# STM32U575 register map
File version: 1.3
CPU: CM33 r0p1, little endian, MPU, FPU, 4 interrupt priority bits
Registers are 32-bit, read-write, reset 0x0 unless marked. A register's access mark holds for its fields unless they carry their own. Offsets are from the block's base; [hi:lo] are bit positions.

## FDCAN1_RAM
Base 0x4000AC00
Same registers: FDCAN1 0x4000A400, SEC_FDCAN1 0x5000A400, SEC_FDCAN1_RAM 0x5000AC00
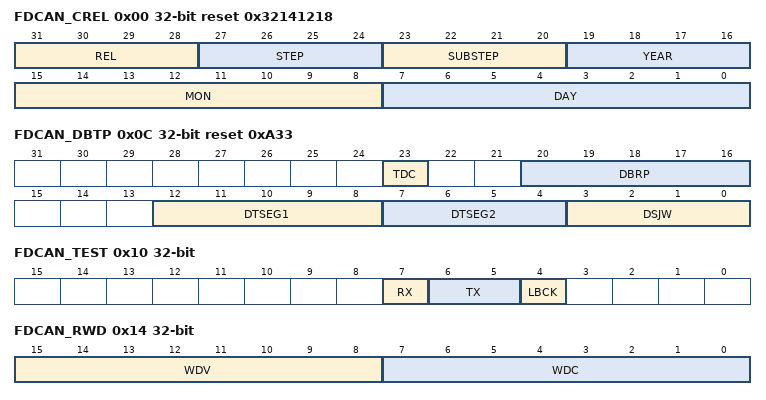
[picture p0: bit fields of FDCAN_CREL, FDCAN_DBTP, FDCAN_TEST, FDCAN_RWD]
0x00 FDCAN_CREL ro reset 0x32141218 — FDCAN Core Release Register
  [31:28] REL — Core release
  [27:24] STEP — Step of Core release
  [23:20] SUBSTEP — Sub-step of Core release
  [19:16] YEAR — Timestamp Year
  [15:8] MON — Timestamp Month
  [7:0] DAY — Timestamp Day
0x04 FDCAN_ENDN ro reset 0x87654321 — FDCAN endian register
  [31:0] ETV — Endiannes Test Value
0x0C FDCAN_DBTP reset 0xA33 — FDCAN Data Bit Timing and Prescaler Register
  [23] TDC — Transceiver Delay Compensation
  [20:16] DBRP — Data BIt Rate Prescaler
  [12:8] DTSEG1 — Data time segment after sample point
  [7:4] DTSEG2 — Data time segment after sample point
  [3:0] DSJW — Synchronization Jump Width
0x10 FDCAN_TEST access per field
  [7] RX ro — Control of Transmit Pin
  [6:5] TX rw — Loop Back mode
  [4] LBCK rw — Loop Back mode
0x14 FDCAN_RWD access per field — FDCAN RAM Watchdog Register
  [15:8] WDV ro — Watchdog value
  [7:0] WDC rw — Watchdog configuration
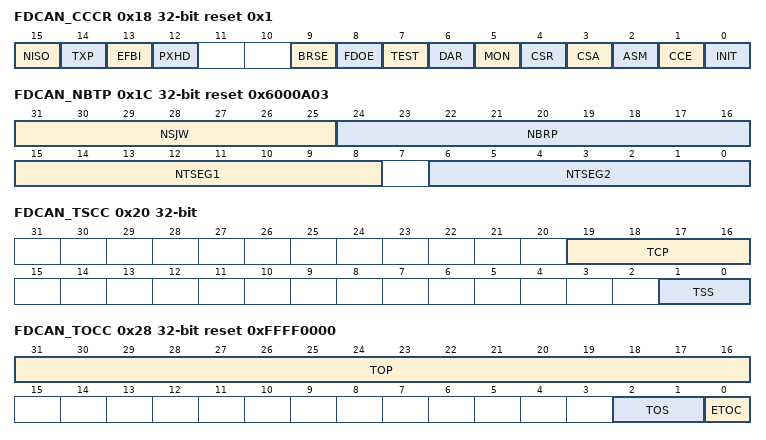
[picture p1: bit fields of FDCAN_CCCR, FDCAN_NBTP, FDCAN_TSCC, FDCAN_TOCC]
0x18 FDCAN_CCCR reset 0x1 — FDCAN CC Control Register
  [15] NISO — Non ISO Operation
  [14] TXP
  [13] EFBI — Edge Filtering during Bus Integration
  [12] PXHD — Protocol Exception Handling Disable
  [9] BRSE — FDCAN Bit Rate Switching
  [8] FDOE — FD Operation Enable
  [7] TEST — Test Mode Enable
  [6] DAR — Disable Automatic Retransmission
  [5] MON — Bus Monitoring Mode
  [4] CSR — Clock Stop Request
  [3] CSA — Clock Stop Acknowledge
  [2] ASM — ASM Restricted Operation Mode
  [1] CCE — Configuration Change Enable
  [0] INIT — Initialization
0x1C FDCAN_NBTP reset 0x6000A03 — FDCAN Nominal Bit Timing and Prescaler Register
  [31:25] NSJW — Nominal (Re)Synchronization Jump Width
  [24:16] NBRP — Bit Rate Prescaler
  [15:8] NTSEG1 — Nominal Time segment before sample point
  [6:0] NTSEG2 — Nominal Time segment after sample point
0x20 FDCAN_TSCC — FDCAN Timestamp Counter Configuration Register
  [19:16] TCP — Timestamp Counter Prescaler
  [1:0] TSS — Timestamp Select
0x24 FDCAN_TSCV — FDCAN Timestamp Counter Value Register
  [15:0] TSC — Timestamp Counter
0x28 FDCAN_TOCC reset 0xFFFF0000 — FDCAN Timeout Counter Configuration Register
  [31:16] TOP — Timeout Period
  [2:1] TOS — Timeout Select
  [0] ETOC — Enable Timeout Counter
0x2C FDCAN_TOCV reset 0xFFFF — FDCAN Timeout Counter Value Register
  [15:0] TOC — Timeout Counter
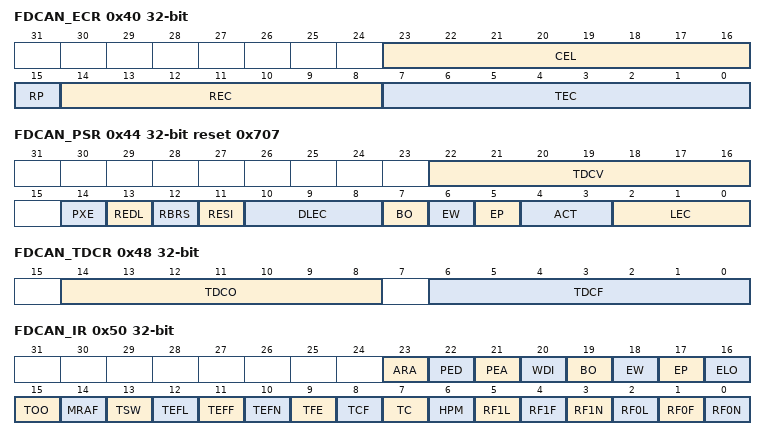
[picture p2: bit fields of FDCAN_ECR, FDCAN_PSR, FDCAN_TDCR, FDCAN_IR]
0x40 FDCAN_ECR access per field — FDCAN Error Counter Register
  [23:16] CEL rw — AN Error Logging
  [15] RP ro — Receive Error Passive
  [14:8] REC ro — Receive Error Counter
  [7:0] TEC ro — Transmit Error Counter
0x44 FDCAN_PSR access per field reset 0x707 — FDCAN Protocol Status Register
  [22:16] TDCV ro — Transmitter Delay Compensation Value
  [14] PXE rw — Protocol Exception Event
  [13] REDL rw — Received FDCAN Message
  [12] RBRS rw — BRS flag of last received FDCAN Message
  [11] RESI rw — ESI flag of last received FDCAN Message
  [10:8] DLEC rw — Data Last Error Code
  [7] BO ro — Bus_Off Status
  [6] EW ro — Warning Status
  [5] EP ro — Error Passive
  [4:3] ACT ro — Activity
  [2:0] LEC rw — Last Error Code
0x48 FDCAN_TDCR — FDCAN Transmitter Delay Compensation Register
  [14:8] TDCO — Transmitter Delay Compensation Offset
  [6:0] TDCF — Transmitter Delay Compensation Filter Window Length
0x50 FDCAN_IR — FDCAN Interrupt Register
  [23] ARA, [22] PED, [21] PEA, [20] WDI, [19] BO, [18] EW, [17] EP, [16] ELO, [15] TOO, [14] MRAF, [13] TSW, [12] TEFL, [11] TEFF, [10] TEFN, [9] TFE, [8] TCF, [7] TC, [6] HPM, [5] RF1L, [4] RF1F, [3] RF1N, [2] RF0L, [1] RF0F, [0] RF0N
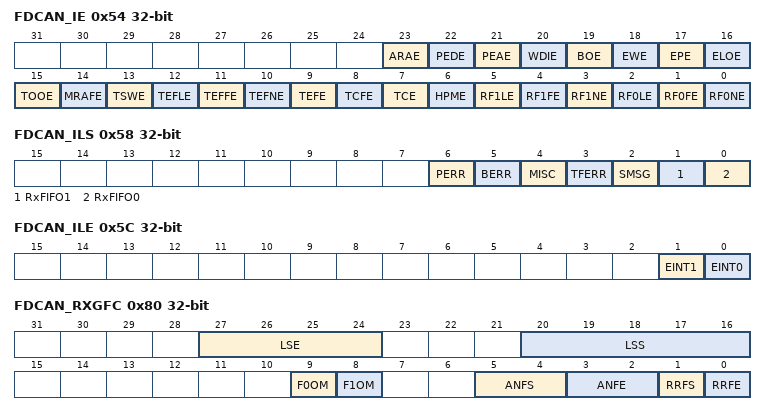
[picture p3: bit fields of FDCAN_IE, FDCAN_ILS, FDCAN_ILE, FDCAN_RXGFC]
0x54 FDCAN_IE — FDCAN Interrupt Enable Register
  [23] ARAE — Access to Reserved Address Enable
  [22] PEDE — Protocol Error in Data Phase Enable
  [21] PEAE — Protocol Error in Arbitration Phase Enable
  [20] WDIE — Watchdog Interrupt Enable
  [19] BOE — Bus_Off Status Enable
  [18] EWE — Warning Status Enable
  [17] EPE — Error Passive Enable
  [16] ELOE — Error Logging Overflow Enable
  [15] TOOE — Timeout Occurred Enable
  [14] MRAFE — Message RAM Access Failure Enable
  [13] TSWE
  [12] TEFLE — Tx Event FIFO Element Lost Enable
  [11] TEFFE — Tx Event FIFO Full Enable
  [10] TEFNE — Tx Event FIFO New Entry Enable
  [9] TEFE — Tx FIFO Empty Enable
  [8] TCFE — Transmission Cancellation Finished Enable
  [7] TCE — Transmission Completed Enable
  [6] HPME — High Priority Message Enable
  [5] RF1LE — Rx FIFO 1 Message Lost Enable
  [4] RF1FE — Rx FIFO 1 Watermark Reached Enable
  [3] RF1NE — Rx FIFO 1 New Message Enable
  [2] RF0LE — Rx FIFO 0 Message Lost Enable
  [1] RF0FE — Rx FIFO 0 Full Enable
  [0] RF0NE — Rx FIFO 0 New Message Enable
0x58 FDCAN_ILS — FDCAN Interrupt Line Select Register
  [6] PERR, [5] BERR, [4] MISC, [3] TFERR, [2] SMSG, [1] RxFIFO1, [0] RxFIFO0
0x5C FDCAN_ILE — FDCAN Interrupt Line Enable Register
  [1] EINT1 — Enable Interrupt Line 1
  [0] EINT0 — Enable Interrupt Line 0
0x80 FDCAN_RXGFC — FDCAN Global Filter Configuration Register
  [27:24] LSE
  [20:16] LSS
  [9] F0OM
  [8] F1OM
  [5:4] ANFS — Accept Non-matching Frames Standard
  [3:2] ANFE — Accept Non-matching Frames Extended
  [1] RRFS — Reject Remote Frames Standard
  [0] RRFE — Reject Remote Frames Extended
0x84 FDCAN_XIDAM reset 0x1FFFFFFF — FDCAN Extended ID and Mask Register
  [28:0] EIDM — Extended ID Mask
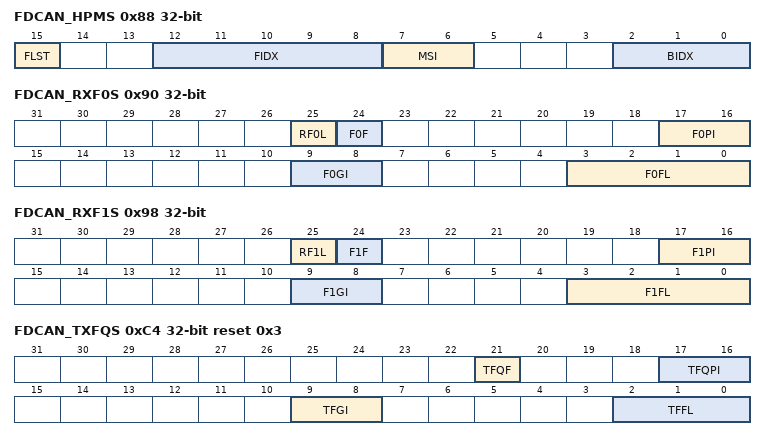
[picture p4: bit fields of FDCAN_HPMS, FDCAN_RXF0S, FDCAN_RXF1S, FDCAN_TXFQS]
0x88 FDCAN_HPMS ro — FDCAN High Priority Message Status Register
  [15] FLST — Filter List
  [12:8] FIDX — Filter Index
  [7:6] MSI — Message Storage Indicator
  [2:0] BIDX — Buffer Index
0x90 FDCAN_RXF0S ro — FDCAN Rx FIFO 0 Status Register
  [25] RF0L — Rx FIFO 0 Message Lost
  [24] F0F — Rx FIFO 0 Full
  [17:16] F0PI — Rx FIFO 0 Put Index
  [9:8] F0GI — Rx FIFO 0 Get Index
  [3:0] F0FL — Rx FIFO 0 Fill Level
0x94 FDCAN_RXF0A — CAN Rx FIFO 0 Acknowledge Register
  [2:0] F0AI — Rx FIFO 0 Acknowledge Index
0x98 FDCAN_RXF1S ro — FDCAN Rx FIFO 1 Status Register
  [25] RF1L — Rx FIFO 1 Message Lost
  [24] F1F — Rx FIFO 1 Full
  [17:16] F1PI — Rx FIFO 1 Put Index
  [9:8] F1GI — Rx FIFO 1 Get Index
  [3:0] F1FL — Rx FIFO 1 Fill Level
0x9C FDCAN_RXF1A — FDCAN Rx FIFO 1 Acknowledge Register
  [2:0] F1AI — Rx FIFO 1 Acknowledge Index
0xC0 FDCAN_TXBC — FDCAN Tx buffer configuration register
  [24] TFQM — Tx FIFO/Queue Mode
0xC4 FDCAN_TXFQS ro reset 0x3 — FDCAN Tx FIFO/Queue Status Register
  [21] TFQF — Tx FIFO/Queue Full
  [17:16] TFQPI — Tx FIFO/Queue Put Index
  [9:8] TFGI
  [2:0] TFFL — Tx FIFO Free Level
0xC8 FDCAN_TXBRP ro — FDCAN Tx Buffer Request Pending Register
  [2:0] TRP — Transmission Request Pending
0xCC FDCAN_TXBAR — FDCAN Tx Buffer Add Request Register
  [2:0] AR — Add Request
0xD0 FDCAN_TXBCR — FDCAN Tx Buffer Cancellation Request Register
  [2:0] CR — Cancellation Request
0xD4 FDCAN_TXBTO ro — FDCAN Tx Buffer Transmission Occurred Register
  [2:0] TO — Transmission Occurred.
0xD8 FDCAN_TXBCF ro — FDCAN Tx Buffer Cancellation Finished Register
  [2:0] CF — Cancellation Finished
0xDC FDCAN_TXBTIE — FDCAN Tx Buffer Transmission Interrupt Enable Register
  [2:0] TIE — Transmission Interrupt Enable
0xE0 FDCAN_TXBCIE — FDCAN Tx Buffer Cancellation Finished Interrupt Enable Register
  [2:0] CFIE — Cancellation Finished Interrupt Enable
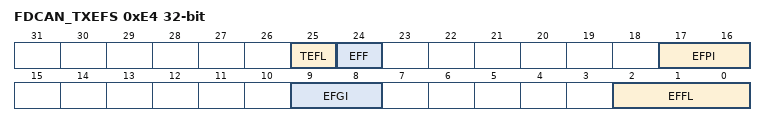
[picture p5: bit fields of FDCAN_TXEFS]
0xE4 FDCAN_TXEFS ro — FDCAN Tx Event FIFO Status Register
  [25] TEFL — Tx Event FIFO Element Lost.
  [24] EFF — Event FIFO Full.
  [17:16] EFPI — Event FIFO Put Index
  [9:8] EFGI — Event FIFO Get Index.
  [2:0] EFFL — Event FIFO Fill Level
0xE8 FDCAN_TXEFA — FDCAN Tx Event FIFO Acknowledge Register
  [1:0] EFAI — Event FIFO Acknowledge Index
0x100 FDCAN_CKDIV — FDCAN CFG clock divider register
  [3:0] PDIV
